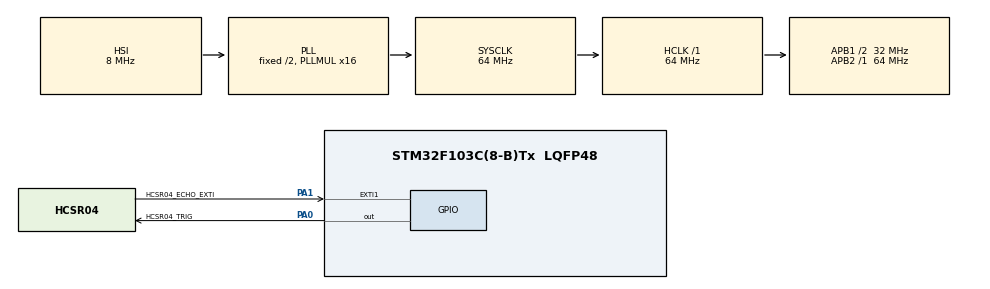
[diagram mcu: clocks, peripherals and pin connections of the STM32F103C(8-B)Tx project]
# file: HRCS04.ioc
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Mcu.Family=STM32F1
Mcu.Name=STM32F103C(8-B)Tx
Mcu.Package=LQFP48
NVIC.EXTI1_IRQn=true\:1\:0\:true\:false\:true\:true\:true\:true
NVIC.PriorityGroup=NVIC_PRIORITYGROUP_4
PA0-WKUP.GPIO_Label=HCSR04_TRIG
PA0-WKUP.Signal=GPIO_Output
PA1.GPIO_Label=HCSR04_ECHO_EXTI
PA1.GPIO_ModeDefaultEXTI=GPIO_MODE_IT_RISING_FALLING
PA1.GPIO_PuPd=GPIO_PULLUP
PA1.Signal=GPXTI1
PA13.Mode=Serial_Wire
PA13.Signal=SYS_JTMS-SWDIO
PA14.Mode=Serial_Wire
PA14.Signal=SYS_JTCK-SWCLK
PD0-OSC_IN.Mode=HSE-External-Oscillator
PD0-OSC_IN.Signal=RCC_OSC_IN
PD1-OSC_OUT.Mode=HSE-External-Oscillator
PD1-OSC_OUT.Signal=RCC_OSC_OUT
ProjectManager.HeapSize=0x200
ProjectManager.StackSize=0x400
ProjectManager.TargetToolchain=MDK-ARM V5.32
RCC.AHBFreq_Value=64000000
RCC.APB1CLKDivider=RCC_HCLK_DIV2
RCC.APB1Freq_Value=32000000
RCC.APB1TimFreq_Value=64000000
RCC.APB2Freq_Value=64000000
RCC.APB2TimFreq_Value=64000000
RCC.HCLKFreq_Value=64000000
RCC.PLLMUL=RCC_PLL_MUL16
RCC.SYSCLKFreq_VALUE=64000000
RCC.SYSCLKSource=RCC_SYSCLKSOURCE_PLLCLK
RCC.USBFreq_Value=64000000
TIM3.Prescaler=63
VP_TIM3_VS_ClockSourceINT.Mode=Internal
board=custom

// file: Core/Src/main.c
/* USER CODE BEGIN Header */
/**
  ******************************************************************************
  * @file           : main.c
  * @brief          : Main program body
  ******************************************************************************
  * @attention
  *
  * Copyright (c) 2024 STMicroelectronics.
  * All rights reserved.
  *
  * This software is licensed under terms that can be found in the LICENSE file
  * in the root directory of this software component.
  * If no LICENSE file comes with this software, it is provided AS-IS.
  *
  ******************************************************************************
  */
/* USER CODE END Header */
#include "main.h"

TIM_HandleTypeDef htim3;

void SystemClock_Config(void);
static void MX_GPIO_Init(void);
static void MX_TIM3_Init(void);

/* USER CODE BEGIN 0 */

// khai bao nguyen mau ham

// khai bao
typedef enum {
	HCSR04_WAIT_EXTI_RISING_STATE,
	HCSR04_WAIT_EXTI_FAILING_STATE,
	HCSR04_COMPLETE_STATE,
	HCSR04_IDLE_STATE
}	HCSR04_State;

HCSR04_State hcsr04_state = HCSR04_IDLE_STATE;

void hcsr04_start();

void hrcs04_start()
{
	HAL_GPIO_WritePin(HCSR04_TRIG_GPIO_Port,HCSR04_TRIG_Pin,1);
	HAL_Delay(1);
	HAL_GPIO_WritePin(HCSR04_TRIG_GPIO_Port,HCSR04_TRIG_Pin,0);
	hcsr04_state = HCSR04_WAIT_EXTI_RISING_STATE;
}

void HAL_GPIO_EXTI_Callback(uint16_t GPIO_Pin)
{
	if(GPIO_Pin == HCSR04_ECHO_EXTI_Pin)
	{
		switch(hcsr04_state)
		{
			case HCSR04_WAIT_EXTI_RISING_STATE :
			{
				if(HAL_GPIO_ReadPin(HCSR04_ECHO_EXTI_GPIO_Port,HCSR04_ECHO_EXTI_Pin) == 0)
				{
					//__HAL_TIM_SetCounter(&htim3,0);
					htim3.Instance->CNT = 0;
					HAL_TIM_Base_Start(&htim3);
					hcsr04_state = HCSR04_WAIT_EXTI_FAILING_STATE;
				}else
				{
					hcsr04_state = HCSR04_IDLE_STATE;
				}
				break;
			}
			case HCSR04_WAIT_EXTI_FAILING_STATE:
			{
				if(HAL_GPIO_ReadPin(HCSR04_ECHO_EXTI_GPIO_Port,HCSR04_ECHO_EXTI_Pin) == 1)
				{

					HAL_TIM_Base_Stop(&htim3);
					hcsr04_state = HCSR04_COMPLETE_STATE;
				}else
				{
					hcsr04_state = HCSR04_IDLE_STATE;
				}
				break;
			}
			default:
			{
				break;
			}
		}
	}
}

void  HCSR04_Complete_Callback(void)
{
	// hien thi lcd
}

void HCSR04_Handler()
{
	switch (hcsr04_state)
	{
		case HCSR04_COMPLETE_STATE:
		{
			float kc = 0.017*htim3.Instance->CNT;
			HCSR04_Complete_Callback();
			break;
		}
		default:
			break;
	}
}

/* USER CODE END 0 */

int main(void)
{

  /* MCU Configuration--------------------------------------------------------*/

  /* Reset of all peripherals, Initializes the Flash interface and the Systick. */
  HAL_Init();

  /* Configure the system clock */
  SystemClock_Config();

  /* Initialize all configured peripherals */
  MX_GPIO_Init();
  MX_TIM3_Init();
  /* USER CODE BEGIN 2 */
	uint32_t t_read;
  /* USER CODE END 2 */

  /* Infinite loop */
  while (1)
  {
		if(HAL_GetTick() - t_read >= 300)
		{
			hcsr04_start();
			HCSR04_Handler();
			t_read = (uint32_t)HAL_GetTick;
		}
  }
}

void SystemClock_Config(void)
{
  RCC_OscInitTypeDef RCC_OscInitStruct = {0};
  RCC_ClkInitTypeDef RCC_ClkInitStruct = {0};

  /** Initializes the RCC Oscillators according to the specified parameters
  * in the RCC_OscInitTypeDef structure.
  */
  RCC_OscInitStruct.OscillatorType = RCC_OSCILLATORTYPE_HSI;
  RCC_OscInitStruct.HSIState = RCC_HSI_ON;
  RCC_OscInitStruct.HSICalibrationValue = RCC_HSICALIBRATION_DEFAULT;
  RCC_OscInitStruct.PLL.PLLState = RCC_PLL_ON;
  RCC_OscInitStruct.PLL.PLLSource = RCC_PLLSOURCE_HSI_DIV2;
  RCC_OscInitStruct.PLL.PLLMUL = RCC_PLL_MUL16;
  if (HAL_RCC_OscConfig(&RCC_OscInitStruct) != HAL_OK)
  {
    Error_Handler();
  }

  /** Initializes the CPU, AHB and APB buses clocks
  */
  RCC_ClkInitStruct.ClockType = RCC_CLOCKTYPE_HCLK|RCC_CLOCKTYPE_SYSCLK
                              |RCC_CLOCKTYPE_PCLK1|RCC_CLOCKTYPE_PCLK2;
  RCC_ClkInitStruct.SYSCLKSource = RCC_SYSCLKSOURCE_PLLCLK;
  RCC_ClkInitStruct.AHBCLKDivider = RCC_SYSCLK_DIV1;
  RCC_ClkInitStruct.APB1CLKDivider = RCC_HCLK_DIV2;
  RCC_ClkInitStruct.APB2CLKDivider = RCC_HCLK_DIV1;

  if (HAL_RCC_ClockConfig(&RCC_ClkInitStruct, FLASH_LATENCY_2) != HAL_OK)
  {
    Error_Handler();
  }
}

static void MX_TIM3_Init(void)
{

  TIM_ClockConfigTypeDef sClockSourceConfig = {0};
  TIM_MasterConfigTypeDef sMasterConfig = {0};

  htim3.Instance = TIM3;
  htim3.Init.Prescaler = 63;
  htim3.Init.CounterMode = TIM_COUNTERMODE_UP;
  htim3.Init.Period = 65535;
  htim3.Init.ClockDivision = TIM_CLOCKDIVISION_DIV1;
  htim3.Init.AutoReloadPreload = TIM_AUTORELOAD_PRELOAD_DISABLE;
  if (HAL_TIM_Base_Init(&htim3) != HAL_OK)
  {
    Error_Handler();
  }
  sClockSourceConfig.ClockSource = TIM_CLOCKSOURCE_INTERNAL;
  if (HAL_TIM_ConfigClockSource(&htim3, &sClockSourceConfig) != HAL_OK)
  {
    Error_Handler();
  }
  sMasterConfig.MasterOutputTrigger = TIM_TRGO_RESET;
  sMasterConfig.MasterSlaveMode = TIM_MASTERSLAVEMODE_DISABLE;
  if (HAL_TIMEx_MasterConfigSynchronization(&htim3, &sMasterConfig) != HAL_OK)
  {
    Error_Handler();
  }

}

static void MX_GPIO_Init(void)
{
  GPIO_InitTypeDef GPIO_InitStruct = {0};

  /* GPIO Ports Clock Enable */
  __HAL_RCC_GPIOD_CLK_ENABLE();
  __HAL_RCC_GPIOA_CLK_ENABLE();

  /*Configure GPIO pin Output Level */
  HAL_GPIO_WritePin(HCSR04_TRIG_GPIO_Port, HCSR04_TRIG_Pin, GPIO_PIN_RESET);

  /*Configure GPIO pin : HCSR04_TRIG_Pin */
  GPIO_InitStruct.Pin = HCSR04_TRIG_Pin;
  GPIO_InitStruct.Mode = GPIO_MODE_OUTPUT_PP;
  GPIO_InitStruct.Pull = GPIO_NOPULL;
  GPIO_InitStruct.Speed = GPIO_SPEED_FREQ_LOW;
  HAL_GPIO_Init(HCSR04_TRIG_GPIO_Port, &GPIO_InitStruct);

  /*Configure GPIO pin : HCSR04_ECHO_EXTI_Pin */
  GPIO_InitStruct.Pin = HCSR04_ECHO_EXTI_Pin;
  GPIO_InitStruct.Mode = GPIO_MODE_IT_RISING_FALLING;
  GPIO_InitStruct.Pull = GPIO_PULLUP;
  HAL_GPIO_Init(HCSR04_ECHO_EXTI_GPIO_Port, &GPIO_InitStruct);

  /* EXTI interrupt init*/
  HAL_NVIC_SetPriority(EXTI1_IRQn, 1, 0);
  HAL_NVIC_EnableIRQ(EXTI1_IRQn);

}

void Error_Handler(void)
{
  __disable_irq();
  while (1)
  {
  }
}
